AUTOSAR XML (schema 4-2-1)
standard types defined: dtRef_const_VOID, dtRef_VOID, boolean, float32, float64, sint16, sint16_least, sint32, sint32_least, sint64, sint8, sint8_least, uint16, uint16_least, uint32, uint32_least, uint64, uint8, uint8_least, boolean_CompuMethod, boolean_DataConstr, float32_DataConstr, float64_DataConstr, sint16_DataConstr, sint16_least_DataConstr, sint32_DataConstr, sint32_least_DataConstr, sint64_DataConstr, sint8_DataConstr, sint8_least_DataConstr, uint16_DataConstr, uint16_least_DataConstr, uint32_DataConstr, uint32_least_DataConstr, uint64_DataConstr, uint8_DataConstr, uint8_least_DataConstr
package /CompuMethod
  compu method CM_ECU_State: identical
  compu method CM_ECU_AliveCnt: identical
  compu method CM_Temperature: phys=raw-40
  compu method CM_SupplyVoltage: phys=raw*0.01
  compu method CM_FaultFlags: identical
  compu method CM_LedCmd: identical
  compu method CM_TargetMode: identical
  compu method CM_Cmd_AliveCnt: identical
  compu method CM_PwmDuty: phys=raw*0.5
  compu method CM_Cmd_Crc8: identical
  compu method CM_FaultCode: identical
  compu method CM_FaultActive: identical
package /DataConstr
  range DC_ECU_State: phys 0..15
  range DC_ECU_AliveCnt: phys 0..15
  range DC_Temperature: phys -40..215
  range DC_SupplyVoltage: phys 0..655.35
  range DC_FaultFlags: phys 0..255
  range DC_LedCmd: phys 0..1
  range DC_TargetMode: phys 0..7
  range DC_Cmd_AliveCnt: phys 0..15
  range DC_PwmDuty: phys 0..100
  range DC_Cmd_Crc8: phys 0..255
  range DC_FaultCode: phys 0..255
  range DC_FaultActive: phys 0..1
package /ComponentTypes
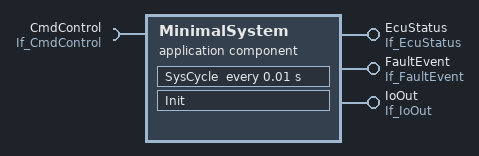
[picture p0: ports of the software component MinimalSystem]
  application sw component type MinimalSystem
    require port CmdControl: required-interface=If_CmdControl
      required-com-specs:
        data-element=LedCmd, init-value=0
        data-element=TargetMode, init-value=0
        data-element=Cmd_AliveCnt, init-value=0
        data-element=If_CmdControl/PwmDuty, init-value=0
        data-element=Cmd_Crc8, init-value=0
    provide port EcuStatus: provided-interface=If_EcuStatus
      provided-com-specs:
        data-element=ECU_State, init-value=0
        data-element=ECU_AliveCnt, init-value=0
        data-element=Temperature, init-value=0
        data-element=SupplyVoltage, init-value=0
        data-element=FaultFlags, init-value=0
    provide port FaultEvent: provided-com-specs=[{data-element=FaultCode, init-value=0}, {data-element=FaultActive, init-value=0}], provided-interface=If_FaultEvent
    provide port IoOut: provided-com-specs=[{data-element=LedState, init-value=0}, {data-element=If_IoOut/PwmDuty, init-value=0}], provided-interface=If_IoOut
    behavior MinimalSystem_IB: data-type-mapping=DataTypeMappingSet
      timing event SysCycleTE: start-on-event=SysCycle, period=0.01
      runnable SysCycle: symbol=MinimalSystem_10ms
        data-read-access:
          5 x access:
            REC_CmdControl_LedCmd: accessed-variable=CmdControl.LedCmd
            REC_CmdControl_TargetMode: accessed-variable=CmdControl.TargetMode
            REC_CmdControl_Cmd_AliveCnt: accessed-variable=CmdControl.Cmd_AliveCnt
            REC_CmdControl_PwmDuty: accessed-variable=CmdControl.PwmDuty
            REC_CmdControl_Cmd_Crc8: accessed-variable=CmdControl.Cmd_Crc8
        data-write-access:
          9 x access:
            SND_EcuStatus_ECU_State: accessed-variable=EcuStatus.ECU_State
            SND_EcuStatus_ECU_AliveCnt: accessed-variable=EcuStatus.ECU_AliveCnt
            SND_EcuStatus_Temperature: accessed-variable=EcuStatus.Temperature
            SND_EcuStatus_SupplyVoltage: accessed-variable=EcuStatus.SupplyVoltage
            SND_EcuStatus_FaultFlags: accessed-variable=EcuStatus.FaultFlags
            SND_FaultEvent_FaultCode: accessed-variable=FaultEvent.FaultCode
            SND_FaultEvent_FaultActive: accessed-variable=FaultEvent.FaultActive
            SND_IoOut_LedState: accessed-variable=IoOut.LedState
            SND_IoOut_PwmDuty: accessed-variable=IoOut.PwmDuty
      runnable Init: symbol=MinimalSystem_Init
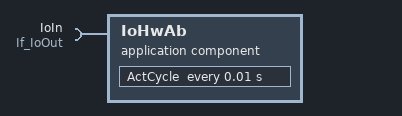
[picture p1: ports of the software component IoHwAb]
  application sw component type IoHwAb
    require port IoIn: required-com-specs=[{data-element=LedState, init-value=0}, {data-element=If_IoOut/PwmDuty, init-value=0}], required-interface=If_IoOut
    behavior IoHwAb_IB: data-type-mapping=DataTypeMappingSet
      timing event ActCycleTE: start-on-event=ActCycle, period=0.01
      runnable ActCycle: symbol=IoHwAb_10ms
        data-read-access:
          access REC_IoIn_LedState: accessed-variable=IoIn.LedState
          access REC_IoIn_PwmDuty: accessed-variable=IoIn.PwmDuty
  swc implementation MinimalSystem_Impl: behavior=MinimalSystem_IB
  swc implementation IoHwAb_Impl: behavior=IoHwAb_IB
package /PortInterfaces
  4 x sender receiver interface:
    If_CmdControl
      5 x data, all with type=AppUInt8:
        LedCmd
        TargetMode
        Cmd_AliveCnt
        PwmDuty
        Cmd_Crc8
    If_EcuStatus
      5 x data:
        ECU_State: type=AppUInt4
        ECU_AliveCnt: type=AppUInt4
        Temperature: type=AppUInt8
        SupplyVoltage: type=AppUInt16
        FaultFlags: type=AppUInt8
    If_FaultEvent
      data FaultCode: type=AppUInt8
      data FaultActive: type=AppUInt1
    If_IoOut
      data LedState: type=AppBoolean
      data PwmDuty: type=AppUInt8
package /DataTypes
  base type uint8_4bit: category=FIXED_LENGTH, base-type-size=4, native-declaration=uint8
  base type uint8_1bit: category=FIXED_LENGTH, base-type-size=1, native-declaration=uint8
  impl type uint4: category=VALUE, base-type=uint8_4bit
  impl type uint1: category=VALUE, base-type=uint8_1bit
  5 x app type:
    AppUInt8: category=VALUE, implementation-data-type=uint8
    AppUInt16: category=VALUE, implementation-data-type=uint16
    AppBoolean: category=BOOLEAN, implementation-data-type=boolean
    AppUInt4: category=VALUE, implementation-data-type=uint4
    AppUInt1: category=VALUE, implementation-data-type=uint1
  data type mapping set DataTypeMappingSet
    data-type-maps:
      application-data-type=AppUInt8, implementation-data-type=uint8
      application-data-type=AppUInt16, implementation-data-type=uint16
      application-data-type=AppBoolean, implementation-data-type=boolean
      application-data-type=AppUInt4, implementation-data-type=uint4
      application-data-type=AppUInt1, implementation-data-type=uint1
